# ATmega3209 register map
Vendor: Atmel; File version: 1.0
CPU: other r0p0, little endian, no MPU, no FPU, 4 interrupt priority bits
Registers are 8-bit, read-write, reset 0x0 unless marked. A register's access mark holds for its fields unless they carry their own. Offsets are from the block's base; [hi:lo] are bit positions; {n}, {i} and the like mark numbered series.

## RTC — Real-Time Counter
Base 0x00000140
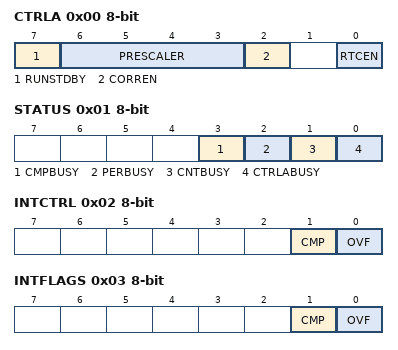
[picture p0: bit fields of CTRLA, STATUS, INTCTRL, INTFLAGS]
0x00 CTRLA — Control A
  [7] RUNSTDBY — Run In Standby
  [6:3] PRESCALER — Prescaling Factor
    0=DIV1 (RTC Clock / 1); 1=DIV2 (RTC Clock / 2); 2=DIV4 (RTC Clock / 4); 3=DIV8 (RTC Clock / 8); 4=DIV16 (RTC Clock / 16); 5=DIV32 (RTC Clock / 32); 6=DIV64 (RTC Clock / 64); 7=DIV128 (RTC Clock / 128); 8=DIV256 (RTC Clock / 256); 9=DIV512 (RTC Clock / 512); 10=DIV1024 (RTC Clock / 1024); 11=DIV2048 (RTC Clock / 2048); 12=DIV4096 (RTC Clock / 4096); 13=DIV8192 (RTC Clock / 8192); 14=DIV16384 (RTC Clock / 16384); 15=DIV32768 (RTC Clock / 32768)
  [2] CORREN — Correction enable
  [0] RTCEN — Enable
0x01 STATUS ro
  [3] CMPBUSY — Comparator Synchronization Busy Flag
  [2] PERBUSY — Period Synchronization Busy Flag
  [1] CNTBUSY — Count Synchronization Busy Flag
  [0] CTRLABUSY — CTRLA Synchronization Busy Flag
0x02 INTCTRL — Interrupt Control
  [1] CMP — Compare Match Interrupt enable
  [0] OVF — Overflow Interrupt enable
0x03 INTFLAGS — Interrupt Flags
  [1] CMP — Compare Match Interrupt
  [0] OVF — Overflow Interrupt Flag
0x04 TEMP — Temporary
0x05 DBGCTRL — Debug control
  [0] DBGRUN — Run in debug
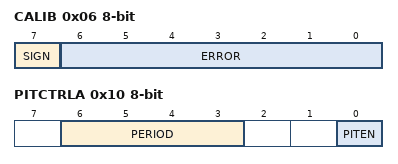
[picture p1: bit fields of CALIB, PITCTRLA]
0x06 CALIB — Calibration
  [7] SIGN — Error Correction Sign Bit
  [6:0] ERROR — Error Correction Value
0x07 CLKSEL — Clock Select
  [1:0] CLKSEL
    0=INT32K (Internal 32kHz OSC); 1=INT1K (Internal 1kHz OSC); 2=TOSC32K (32KHz Crystal OSC); 3=EXTCLK (External Clock)
0x08 CNT 16-bit (reset mask 0xFF) — Counter
0x0A PER 16-bit (reset mask 0xFF) — Period
0x0C CMP 16-bit (reset mask 0xFF) — Compare
0x10 PITCTRLA — PIT Control A
  [6:3] PERIOD
    0=OFF; 1=CYC4 (RTC Clock Cycles 4); 2=CYC8 (RTC Clock Cycles 8); 3=CYC16 (RTC Clock Cycles 16); 4=CYC32 (RTC Clock Cycles 32); 5=CYC64 (RTC Clock Cycles 64); 6=CYC128 (RTC Clock Cycles 128); 7=CYC256 (RTC Clock Cycles 256); 8=CYC512 (RTC Clock Cycles 512); 9=CYC1024 (RTC Clock Cycles 1024); 10=CYC2048 (RTC Clock Cycles 2048); 11=CYC4096 (RTC Clock Cycles 4096); 12=CYC8192 (RTC Clock Cycles 8192); 13=CYC16384 (RTC Clock Cycles 16384); 14=CYC32768 (RTC Clock Cycles 32768)
  [0] PITEN — Enable
0x11 PITSTATUS ro
  [0] CTRLBUSY — CTRLA Synchronization Busy Flag
0x12 PITINTCTRL — PIT Interrupt Control
  [0] PI — Periodic Interrupt
0x13 PITINTFLAGS — PIT Interrupt Flags
  [0] PI — Periodic Interrupt
0x15 PITDBGCTRL — PIT Debug control
  [0] DBGRUN — Run in debug

## SIGROW — Signature row
Base 0x00001100
{0x0+i} DEVICEID{i} ro (i=0..2) — Device ID Byte {i}
{0x3+i} SERNUM{i} ro (i=0..9) — Serial Number Byte {i}
0x14 OSCCAL32K ro — Oscillator Calibration for 32kHz ULP
0x18 OSCCAL16M0 ro — Oscillator Calibration 16 MHz Byte 0
0x19 OSCCAL16M1 ro — Oscillator Calibration 16 MHz Byte 1
0x1A OSCCAL20M0 ro — Oscillator Calibration 20 MHz Byte 0
0x1B OSCCAL20M1 ro — Oscillator Calibration 20 MHz Byte 1
0x20 TEMPSENSE0 ro — Temperature Sensor Calibration Byte 0
0x21 TEMPSENSE1 ro — Temperature Sensor Calibration Byte 1
0x22 OSC16ERR3V ro — OSC16 error at 3V
0x23 OSC16ERR5V ro — OSC16 error at 5V
0x24 OSC20ERR3V ro — OSC20 error at 3V
0x25 OSC20ERR5V ro — OSC20 error at 5V
0x2F CHECKSUM1 ro — CRC Checksum Byte 1

## SLPCTRL — Sleep Controller
Base 0x00000050
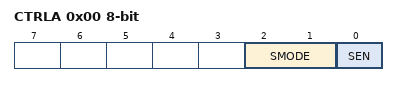
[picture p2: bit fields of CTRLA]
0x00 CTRLA — Control
  [2:1] SMODE — Sleep mode
    0=IDLE (Idle mode); 1=STDBY (Standby Mode); 2=PDOWN (Power-down Mode)
  [0] SEN — Sleep enable

## SPI0 — Serial Peripheral Interface
Base 0x000008C0
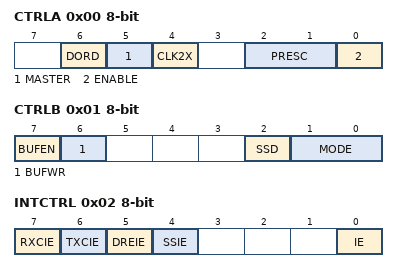
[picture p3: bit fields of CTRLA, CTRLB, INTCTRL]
0x00 CTRLA — Control A
  [6] DORD — Data Order Setting
  [5] MASTER — Host Operation Enable
  [4] CLK2X — Enable Double Speed
  [2:1] PRESC — Prescaler
    0=DIV4 (System Clock / 4); 1=DIV16 (System Clock / 16); 2=DIV64 (System Clock / 64); 3=DIV128 (System Clock / 128)
  [0] ENABLE — Enable Module
0x01 CTRLB — Control B
  [7] BUFEN — Buffer Mode Enable
  [6] BUFWR — Buffer Write Mode
  [2] SSD — Client Select Disable
  [1:0] MODE — SPI Mode
    {v}=SPI Mode {v} (v=0..3)
0x02 INTCTRL — Interrupt Control
  [7] RXCIE — Receive Complete Interrupt Enable
  [6] TXCIE — Transfer Complete Interrupt Enable
  [5] DREIE — Data Register Empty Interrupt Enable
  [4] SSIE — Client Select Trigger Interrupt Enable
  [0] IE — Interrupt Enable
0x03 INTFLAGS — Interrupt Flags
  [7] IF — Interrupt Flag
  [7] RXCIF — Receive Complete Interrupt Flag
  [6] TXCIF — Transfer Complete Interrupt Flag
  [6] WRCOL — Write Collision
  [5] DREIF — Data Register Empty Interrupt Flag
  [4] SSIF — Client Select Trigger Interrupt Flag
  [0] BUFOVF — Buffer Overflow
0x04 DATA
